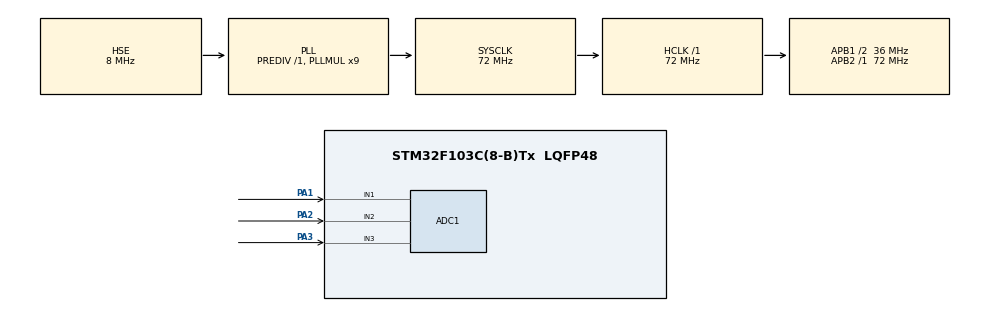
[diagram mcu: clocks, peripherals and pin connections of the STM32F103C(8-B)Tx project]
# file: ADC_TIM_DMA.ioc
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ADC1.Channel-1\#ChannelRegularConversion=ADC_CHANNEL_1
ADC1.Channel-2\#ChannelRegularConversion=ADC_CHANNEL_2
ADC1.Channel-3\#ChannelRegularConversion=ADC_CHANNEL_3
ADC1.ExternalTrigConv=ADC_EXTERNALTRIGCONV_T3_TRGO
ADC1.NbrOfConversion=3
ADC1.NbrOfConversionFlag=1
ADC1.Rank-1\#ChannelRegularConversion=1
ADC1.Rank-2\#ChannelRegularConversion=2
ADC1.Rank-3\#ChannelRegularConversion=3
ADC1.SamplingTime-1\#ChannelRegularConversion=ADC_SAMPLETIME_1CYCLE_5
ADC1.SamplingTime-2\#ChannelRegularConversion=ADC_SAMPLETIME_1CYCLE_5
ADC1.SamplingTime-3\#ChannelRegularConversion=ADC_SAMPLETIME_1CYCLE_5
ADC1.master=1
Dma.ADC1.0.Direction=DMA_PERIPH_TO_MEMORY
Dma.ADC1.0.Instance=DMA1_Channel1
Dma.ADC1.0.MemDataAlignment=DMA_MDATAALIGN_WORD
Dma.ADC1.0.MemInc=DMA_MINC_ENABLE
Dma.ADC1.0.Mode=DMA_CIRCULAR
Dma.ADC1.0.PeriphDataAlignment=DMA_PDATAALIGN_WORD
Dma.ADC1.0.PeriphInc=DMA_PINC_DISABLE
Dma.ADC1.0.Priority=DMA_PRIORITY_LOW
Dma.Request0=ADC1
Mcu.Family=STM32F1
Mcu.Name=STM32F103C(8-B)Tx
Mcu.Package=LQFP48
NVIC.DMA1_Channel1_IRQn=true\:0\:0\:false\:false\:true\:false\:true\:true
NVIC.PriorityGroup=NVIC_PRIORITYGROUP_4
PA1.Signal=ADCx_IN1
PA13.Mode=Serial_Wire
PA13.Signal=SYS_JTMS-SWDIO
PA14.Mode=Serial_Wire
PA14.Signal=SYS_JTCK-SWCLK
PA2.Signal=ADCx_IN2
PA3.Signal=ADCx_IN3
PD0-OSC_IN.Mode=HSE-External-Oscillator
PD0-OSC_IN.Signal=RCC_OSC_IN
PD1-OSC_OUT.Mode=HSE-External-Oscillator
PD1-OSC_OUT.Signal=RCC_OSC_OUT
ProjectManager.HeapSize=0x200
ProjectManager.StackSize=0x400
ProjectManager.TargetToolchain=MDK-ARM V5.32
RCC.ADCPresc=RCC_ADCPCLK2_DIV6
RCC.AHBFreq_Value=72000000
RCC.APB1CLKDivider=RCC_HCLK_DIV2
RCC.APB1Freq_Value=36000000
RCC.APB1TimFreq_Value=72000000
RCC.APB2Freq_Value=72000000
RCC.APB2TimFreq_Value=72000000
RCC.HCLKFreq_Value=72000000
RCC.PLLMUL=RCC_PLL_MUL9
RCC.PLLSourceVirtual=RCC_PLLSOURCE_HSE
RCC.SYSCLKFreq_VALUE=72000000
RCC.SYSCLKSource=RCC_SYSCLKSOURCE_PLLCLK
RCC.USBFreq_Value=72000000
SH.ADCx_IN1.0=ADC1_IN1,IN1
SH.ADCx_IN2.0=ADC1_IN2,IN2
SH.ADCx_IN3.0=ADC1_IN3,IN3
TIM3.Period=1000-1
TIM3.Prescaler=72-1
TIM3.TIM_MasterOutputTrigger=TIM_TRGO_UPDATE
VP_TIM3_VS_ClockSourceINT.Mode=Internal
board=custom

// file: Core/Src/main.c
/* USER CODE BEGIN Header */
/**
  ******************************************************************************
  * @file           : main.c
  * @brief          : Main program body
  ******************************************************************************
  * @attention
  *
  * Copyright (c) 2025 STMicroelectronics.
  * All rights reserved.
  *
  * This software is licensed under terms that can be found in the LICENSE file
  * in the root directory of this software component.
  * If no LICENSE file comes with this software, it is provided AS-IS.
  *
  ******************************************************************************
  */
/* USER CODE END Header */
#include "main.h"
#include "adc.h"
#include "dma.h"
#include "tim.h"
#include "gpio.h"

/* USER CODE BEGIN PD */
#define NoS 100
/* USER CODE END PD */

/* USER CODE BEGIN PV */
uint32_t adc_values[NoS*3];
uint16_t adc_value1 = 0;
uint16_t adc_value2 = 0;
uint16_t adc_value3 = 0;
/* USER CODE END PV */

void SystemClock_Config(void);

int main(void)
{

  /* MCU Configuration--------------------------------------------------------*/

  /* Reset of all peripherals, Initializes the Flash interface and the Systick. */
  HAL_Init();

  /* Configure the system clock */
  SystemClock_Config();

  /* Initialize all configured peripherals */
  MX_GPIO_Init();
  MX_DMA_Init();
  MX_ADC1_Init();
  MX_TIM3_Init();
  /* USER CODE BEGIN 2 */

	HAL_TIM_Base_Start(&htim3);
	HAL_ADC_Start_DMA(&hadc1, adc_values, NoS*3);

  /* USER CODE END 2 */

  /* Infinite loop */
  while (1)
  {

  }
}

void SystemClock_Config(void)
{
  RCC_OscInitTypeDef RCC_OscInitStruct = {0};
  RCC_ClkInitTypeDef RCC_ClkInitStruct = {0};
  RCC_PeriphCLKInitTypeDef PeriphClkInit = {0};

  /** Initializes the RCC Oscillators according to the specified parameters
  * in the RCC_OscInitTypeDef structure.
  */
  RCC_OscInitStruct.OscillatorType = RCC_OSCILLATORTYPE_HSE;
  RCC_OscInitStruct.HSEState = RCC_HSE_ON;
  RCC_OscInitStruct.HSEPredivValue = RCC_HSE_PREDIV_DIV1;
  RCC_OscInitStruct.HSIState = RCC_HSI_ON;
  RCC_OscInitStruct.PLL.PLLState = RCC_PLL_ON;
  RCC_OscInitStruct.PLL.PLLSource = RCC_PLLSOURCE_HSE;
  RCC_OscInitStruct.PLL.PLLMUL = RCC_PLL_MUL9;
  if (HAL_RCC_OscConfig(&RCC_OscInitStruct) != HAL_OK)
  {
    Error_Handler();
  }

  /** Initializes the CPU, AHB and APB buses clocks
  */
  RCC_ClkInitStruct.ClockType = RCC_CLOCKTYPE_HCLK|RCC_CLOCKTYPE_SYSCLK
                              |RCC_CLOCKTYPE_PCLK1|RCC_CLOCKTYPE_PCLK2;
  RCC_ClkInitStruct.SYSCLKSource = RCC_SYSCLKSOURCE_PLLCLK;
  RCC_ClkInitStruct.AHBCLKDivider = RCC_SYSCLK_DIV1;
  RCC_ClkInitStruct.APB1CLKDivider = RCC_HCLK_DIV2;
  RCC_ClkInitStruct.APB2CLKDivider = RCC_HCLK_DIV1;

  if (HAL_RCC_ClockConfig(&RCC_ClkInitStruct, FLASH_LATENCY_2) != HAL_OK)
  {
    Error_Handler();
  }
  PeriphClkInit.PeriphClockSelection = RCC_PERIPHCLK_ADC;
  PeriphClkInit.AdcClockSelection = RCC_ADCPCLK2_DIV6;
  if (HAL_RCCEx_PeriphCLKConfig(&PeriphClkInit) != HAL_OK)
  {
    Error_Handler();
  }
}

/* USER CODE BEGIN 4 */
void HAL_ADC_ConvCpltCallback(ADC_HandleTypeDef* hadc)
{
	uint32_t sum1=0;
	uint32_t sum2=0;
	uint32_t sum3=0;
	for(int i=0; i<NoS; i++){
		// sum = sum + adc_values[i];
		sum1 += adc_values[i*3 + 0];
		sum2 += adc_values[i*3 + 1];
		sum3 += adc_values[i*3 + 2];
	}
	adc_value1 = sum1 / NoS;
	adc_value2 = sum2 / NoS;
	adc_value3 = sum3 / NoS;
}
/* USER CODE END 4 */

void Error_Handler(void)
{
  __disable_irq();
  while (1)
  {
  }
}
